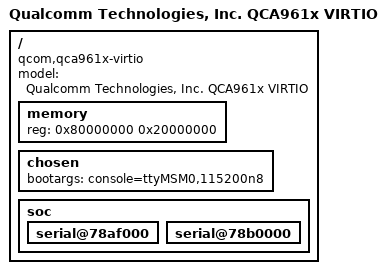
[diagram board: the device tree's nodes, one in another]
/* Copyright (c) 2014, The Linux Foundation. All rights reserved.
 *
 * This program is free software; you can redistribute it and/or modify
 * it under the terms of the GNU General Public License version 2 and
 * only version 2 as published by the Free Software Foundation.
 *
 * This program is distributed in the hope that it will be useful,
 * but WITHOUT ANY WARRANTY; without even the implied warranty of
 * MERCHANTABILITY or FITNESS FOR A PARTICULAR PURPOSE.  See the
 * GNU General Public License for more details.
 */

#include "qcom-qca961x.dtsi"

/ {
	model = "Qualcomm Technologies, Inc. QCA961x VIRTIO";
	compatible = "qcom,qca961x-virtio", "qcom,qca961x";

	memory {
		device_type = "memory";
		reg = <0x80000000 0x20000000>; /* 512MB */
	};

	chosen {
		bootargs = "console=ttyMSM0,115200n8";
	};

	soc {
		serial@78af000 {
			status = "ok";
		};

		serial@78b0000 {
			status = "ok";
		};
	};
};
